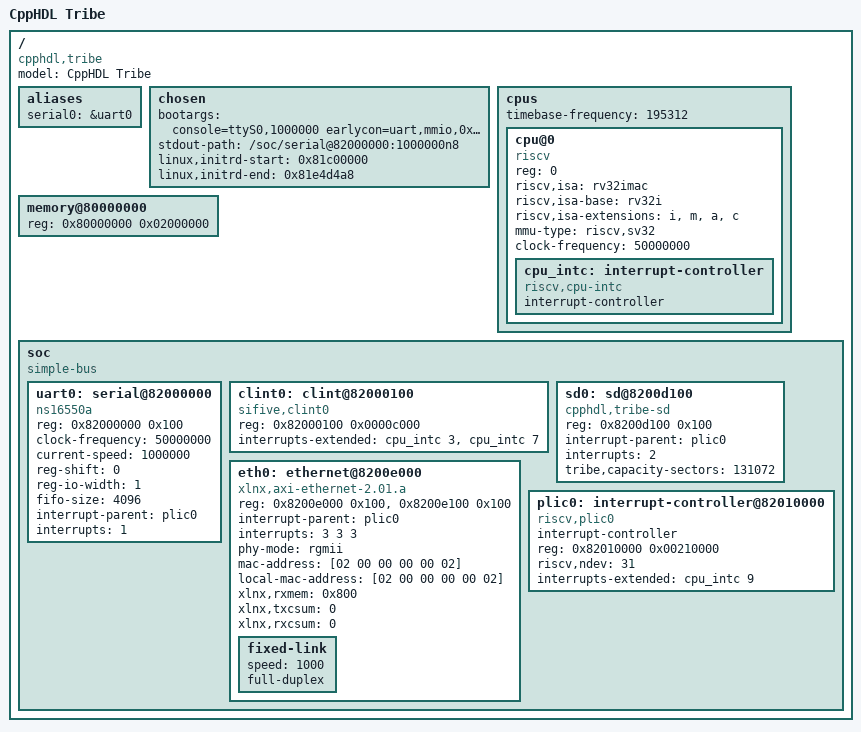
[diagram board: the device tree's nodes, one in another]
/dts-v1/;

/ {
	model = "CppHDL Tribe";
	#address-cells = <1>;
	#size-cells = <1>;
	compatible = "cpphdl,tribe";

	aliases {
		serial0 = &uart0;
	};

	chosen {
		bootargs = "console=ttyS0,1000000 earlycon=uart,mmio,0x82000000 unaligned_scalar_speed=slow";
		stdout-path = "/soc/serial@82000000:1000000n8";
		linux,initrd-start = <0x81c00000>;
		linux,initrd-end = <0x81e4d4a8>;
	};

	cpus {
		#address-cells = <1>;
		#size-cells = <0>;
		timebase-frequency = <195312>;

		cpu@0 {
			device_type = "cpu";
			reg = <0>;
			status = "okay";
			compatible = "riscv";
			riscv,isa = "rv32imac";
			riscv,isa-base = "rv32i";
			riscv,isa-extensions = "i", "m", "a", "c";
			mmu-type = "riscv,sv32";
			clock-frequency = <50000000>;

			cpu_intc: interrupt-controller {
				#interrupt-cells = <1>;
				interrupt-controller;
				compatible = "riscv,cpu-intc";
			};
		};
	};

	memory@80000000 {
		device_type = "memory";
		reg = <0x80000000 0x02000000>;
	};

	soc {
		#address-cells = <1>;
		#size-cells = <1>;
		compatible = "simple-bus";
		ranges;

		uart0: serial@82000000 {
			compatible = "ns16550a";
			reg = <0x82000000 0x100>;
			clock-frequency = <50000000>;
			current-speed = <1000000>;
			reg-shift = <0>;
			reg-io-width = <1>;
			fifo-size = <4096>;
			interrupt-parent = <&plic0>;
			interrupts = <1>;
			status = "okay";
		};

		clint0: clint@82000100 {
			compatible = "sifive,clint0", "riscv,clint0";
			reg = <0x82000100 0x0000c000>;
			interrupts-extended = <&cpu_intc 3 &cpu_intc 7>;
		};

		sd0: sd@8200d100 {
			compatible = "cpphdl,tribe-sd";
			reg = <0x8200d100 0x100>;
			interrupt-parent = <&plic0>;
			interrupts = <2>;
			tribe,capacity-sectors = <131072>;
			status = "okay";
		};

		eth0: ethernet@8200e000 {
			compatible = "xlnx,axi-ethernet-2.01.a";
			reg = <0x8200e000 0x100>, <0x8200e100 0x100>;
			interrupt-parent = <&plic0>;
			interrupts = <3 3 3>;
			phy-mode = "rgmii";
			mac-address = [02 00 00 00 00 02];
			local-mac-address = [02 00 00 00 00 02];
			xlnx,rxmem = <0x800>;
			xlnx,txcsum = <0>;
			xlnx,rxcsum = <0>;
			status = "okay";
			fixed-link {
				speed = <1000>;
				full-duplex;
			};
		};

		plic0: interrupt-controller@82010000 {
			#interrupt-cells = <1>;
			interrupt-controller;
			compatible = "riscv,plic0";
			reg = <0x82010000 0x00210000>;
			riscv,ndev = <31>;
			interrupts-extended = <&cpu_intc 9>;
		};
	};
};
